# APM32F411 register map
Vendor: Geehy; File version: 2024.11.05
CPU: CM4 r1p0, little endian, 3 interrupt priority bits
Registers are 32-bit, read-write, reset 0x0 unless marked. A register's access mark holds for its fields unless they carry their own. Offsets are from the block's base; [hi:lo] are bit positions; {n}, {i} and the like mark numbered series; 'fields as' and 'values as' point back to an identical list.

## CAN1 — Controller area network
Base 0x40006400
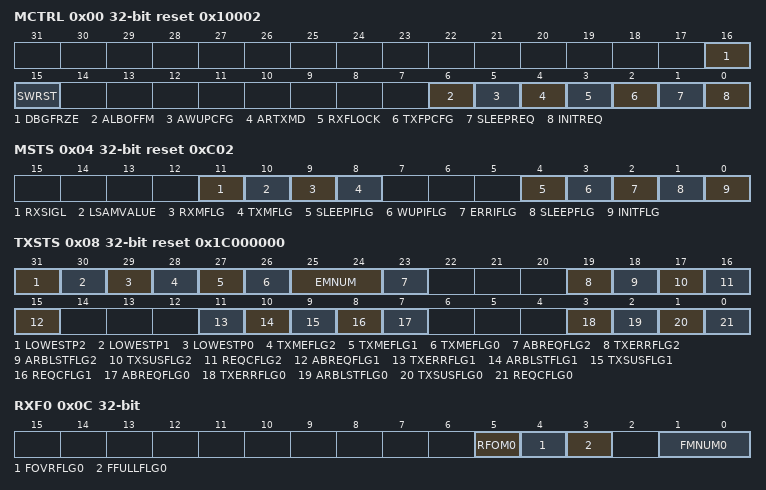
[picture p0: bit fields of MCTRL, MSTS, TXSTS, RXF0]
0x00 MCTRL reset 0x10002 — Governs the CAN controller operation modes and configuration, including initialization/sleep requests, FIFO lock, automatic retransmission, and software reset.
  [16] DBGFRZE — Determines whether the CAN can continue receiving/transmitting during debugging. 0: CAN is active, 1: CAN is frozen (no receive/transmit) but registers remain accessible.
    0=DISABLED (CAN continues normal operation in debug mode.); 1=ENABLED (CAN is frozen (no receive/transmit) during debug mode.)
  [15] SWRST — Forces a reset of the CAN controller when set to 1. Hardware clears this bit automatically once reset is performed, placing CAN in sleep mode.
    0=NO_RESET (Normal operation.); 1=FORCE_RESET (Reset the CAN controller, hardware clears this bit.)
  [6] ALBOFFM — Determines the condition for recovering from bus-off. 0: Software requests init mode then clear it after 128 occurrences of 11 recessive bits. 1: Hardware automatically recovers from bus-off.
    0=SOFTWARE (Need to request init mode and clear it to leave bus-off.); 1=AUTO (Hardware automatically recovers from bus-off.)
  [5] AWUPCFG — Selects how the CAN wakes from sleep mode. 0: Software must clear SLEEPREQ. 1: Hardware automatically clears SLEEPREQ upon detecting CAN traffic.
    0=SW_WAKEUP (Exit from sleep requires software to clear SLEEPREQ bit.); 1=HW_WAKEUP (Automatically exit sleep upon receiving CAN message.)
  [4] ARTXMD — Controls automatic retransmission. 0: Retransmit on error or arbitration loss until success. 1: Transmit only once.
    0=AUTO_RETX_ENABLED (CAN will keep retrying a failed transmission.); 1=AUTO_RETX_DISABLED (Transmit only once, no automatic retry.)
  [3] RXFLOCK — Determines FIFO behavior upon overrun. 0: Overwritten by the new message. 1: New message is discarded when FIFO is full.
    0=UNLOCKED (Overwrite oldest message if FIFO is full.); 1=LOCKED (Discard new message if FIFO is full.)
  [2] TXFPCFG — Determines how priority is chosen when multiple transmit mailboxes are pending. 0: Priority by message identifier (lower ID = higher priority). 1: Priority by transmit request order.
    0=ID_PRIORITY (Use message ID to arbitrate priority.); 1=REQUEST_PRIORITY (Use the sequence of transmission requests.)
  [1] SLEEPREQ — Requests entering sleep mode (1) or exiting it (0). When in sleep mode, the CAN clock stops working, reducing power consumption. If AWUPCFG is set, the controller can automatically clear this bit upon detecting CAN activity.
    0=SLEEPREQ_CLEAR (No sleep request (normal operation).); 1=SLEEPREQ_SET (Request to enter sleep mode.)
  [0] INITREQ — Requests entering initialization mode (1) or exiting it (0). In initialization mode, the CAN configuration (bit timing, filters, etc.) can be modified. Message reception/transmission is disabled in init mode.
    0=NORMAL_MODE (Exit initialization mode.); 1=INIT_MODE (Enter initialization mode.)
0x04 MSTS reset 0xC02 — Reflects the controller's current mode (initialization/sleep), active interrupts, and transmit/receive states. Some flags are set by hardware and cleared by writing 1 (RC_W1).
  [11] RXSIGL ro — Shows the current real-time level of the CAN_RX pin. Set/cleared by hardware.
    0=DOMINANT (Rx pin is currently at a dominant (0) level.); 1=RECESSIVE (Rx pin is currently at a recessive (1) level.)
  [10] LSAMVALUE ro — Displays the last sampled level on the CAN_RX pin. Set/cleared by hardware.
    0=DOMINANT (Sampled a dominant (logic 0) level.); 1=RECESSIVE (Sampled a recessive (logic 1) level.)
  [9] RXMFLG ro — Indicates whether CAN is currently receiving (1) or not (0). Set/cleared by hardware.
    0=NOT_RECEIVING (CAN is not in reception mode.); 1=RECEIVING (CAN is currently receiving a frame.)
  [8] TXMFLG ro — Indicates whether CAN is currently transmitting (1) or not (0). Set/cleared by hardware.
    0=NOT_TRANSMITTING (CAN is not in transmission mode.); 1=TRANSMITTING (CAN is in the process of sending a frame.)
  [4] SLEEPIFLG — Set by hardware when entering sleep mode; cleared by writing 1 or by exiting sleep mode.
    0=NO_SLEEP_INT (Not entered sleep mode or flag cleared.); 1=SLEEP_INT (Entered sleep mode.)
  [3] WUPIFLG — Set by hardware when waking up from sleep mode; cleared by writing 1.
    0=NO_WAKEUP_INT (Did not wake up from sleep or flag cleared.); 1=WAKEUP_INT (CAN woke up from sleep mode.)
  [2] ERRIFLG — Set by hardware when an error interrupt event occurs; cleared by writing 1.
    0=NO_ERROR_INT (No new error interrupt has occurred.); 1=ERROR_INT (An error interrupt event has occurred.)
  [1] SLEEPFLG ro — Indicates whether the CAN is in sleep mode (1) or not (0). Set/cleared by hardware.
    0=AWAKE (CAN is not in sleep mode.); 1=ASLEEP (CAN is in sleep mode.)
  [0] INITFLG ro — Indicates whether the CAN is in initialization mode (1) or not (0). Set/cleared by hardware.
    0=NORMAL_MODE (CAN is not in initialization mode.); 1=INIT_MODE (CAN is in initialization mode.)
0x08 TXSTS access per field reset 0x1C000000 — Provides status for the three transmit mailboxes (request completion, arbitration lost, error flags, abort requests, empty mailboxes, etc.). Certain bits are set or cleared by hardware upon transmission events.
  [31] LOWESTP2 ro — Indicates mailbox 2 is the lowest priority among mailboxes waiting to transmit (only relevant when multiple mailboxes are pending).
    0=NOT_LOWEST (Mailbox 2 is not the lowest priority transmitter); 1=LOWEST (Mailbox 2 is the lowest priority transmitter)
  [30] LOWESTP1 ro — Indicates mailbox 1 is the lowest priority among mailboxes waiting to transmit (only relevant when multiple mailboxes are pending).
    0=NOT_LOWEST (Mailbox 1 is not the lowest priority transmitter); 1=LOWEST (Mailbox 1 is the lowest priority transmitter)
  [29] LOWESTP0 ro — Indicates mailbox 0 is the lowest priority among mailboxes waiting to transmit (only relevant when multiple mailboxes are pending).
    0=NOT_LOWEST (Mailbox 0 is not the lowest priority transmitter); 1=LOWEST (Mailbox 0 is the lowest priority transmitter)
  [28] TXMEFLG2 ro — Set by hardware when mailbox 2 is empty. Cleared by hardware when a message is pending.
    0=NOT_EMPTY (Message pending in mailbox 2); 1=EMPTY (Mailbox 2 contains no message)
  [27] TXMEFLG1 ro — Set by hardware when mailbox 1 is empty. Cleared by hardware when a message is pending.
    0=NOT_EMPTY (Message pending in mailbox 1); 1=EMPTY (Mailbox 1 contains no message)
  [26] TXMEFLG0 ro — Set by hardware when mailbox 0 is empty. Cleared by hardware when a message is pending.
    0=NOT_EMPTY (Message pending in mailbox 0); 1=EMPTY (Mailbox 0 contains no message)
  [25:24] EMNUM ro — Indicates the index of an empty mailbox or the next mailbox to be transmitted if not all are empty.
  [23] ABREQFLG2 rw — Software sets this bit to abort a pending transmit request in mailbox 2. Cleared by hardware when no message is waiting or after successful abort.
    0=NO_ABORT (No abort request); 1=ABORT (Abort the current transmit request)
  [19] TXERRFLG2 rw — Set by hardware when mailbox 2 fails to transmit. Cleared by writing 1.
    0=NO_ERROR (No transmission error); 1=ERROR (Transmission failed for mailbox 2)
  [18] ARBLSTFLG2 rw — Set by hardware if mailbox 2 loses arbitration. Cleared by writing 1.
    0=NO_LOSS (No arbitration lost for mailbox 2); 1=LOST (Mailbox 2 lost arbitration)
  [17] TXSUSFLG2 rw — Set by hardware when the last transmission attempt for mailbox 2 succeeds. Cleared by writing 1.
    0=FAIL (Last attempt failed); 1=SUCCESS (Last attempt succeeded)
  [16] REQCFLG2 rw — Set by hardware when transmission or abort is completed for mailbox 2. Cleared by writing 1.
    0=IN_PROGRESS (Transmission or abort not yet completed); 1=COMPLETED (Transmission or abort completed)
  [15] ABREQFLG1 rw — Software sets this bit to abort a pending transmit request in mailbox 1. Cleared by hardware when no message is waiting or after successful abort.
    values as ABREQFLG2
  [11] TXERRFLG1 rw — Set by hardware when mailbox 1 fails to transmit. Cleared by writing 1.
    0=NO_ERROR (No transmission error); 1=ERROR (Transmission failed for mailbox 1)
  [10] ARBLSTFLG1 rw — Set by hardware if mailbox 1 loses arbitration. Cleared by writing 1.
    0=NO_LOSS (No arbitration lost for mailbox 1); 1=LOST (Mailbox 1 lost arbitration)
  [9] TXSUSFLG1 rw — Set by hardware when the last transmission attempt for mailbox 1 succeeds. Cleared by writing 1.
    values as TXSUSFLG2
  [8] REQCFLG1 rw — Set by hardware when transmission or abort is completed for mailbox 1. Cleared by writing 1.
    values as REQCFLG2
  [7] ABREQFLG0 rw — Software sets this bit to abort a pending transmit request in mailbox 0. Cleared by hardware when no message is waiting or after successful abort.
    values as ABREQFLG2
  [3] TXERRFLG0 rw — Set by hardware when mailbox 0 fails to transmit. Cleared by writing 1.
    0=NO_ERROR (No transmission error); 1=ERROR (Transmission failed for mailbox 0)
  [2] ARBLSTFLG0 rw — Set by hardware if mailbox 0 loses arbitration. Cleared by writing 1.
    0=NO_LOSS (No arbitration lost for mailbox 0); 1=LOST (Mailbox 0 lost arbitration)
  [1] TXSUSFLG0 rw — Set by hardware when the last transmission attempt for mailbox 0 succeeds. Cleared by writing 1.
    values as TXSUSFLG2
  [0] REQCFLG0 rw — Set by hardware when transmission or abort is completed for mailbox 0. Cleared by writing 1.
    values as REQCFLG2
0x0C RXF0 access per field — Reflects the current state of FIFO0, including the number of messages stored, full/overrun flags, and the release output mailbox control.
  [5] RFOM0 rw — If 1, releases the output mailbox of FIFO0, allowing the next stored message to be accessed. Hardware clears this bit to 0 after the release.
    0=NO_RELEASE (Output mailbox is not released.); 1=RELEASE (Frees FIFO0 output mailbox to access next message.)
  [4] FOVRFLG0 rw — Set by hardware when a new message arrives while FIFO0 is full. Cleared by software writing 1.
    0=NO_OVERRUN (No overrun has occurred or flag is cleared.); 1=OVERRUN_OCCURRED (FIFO0 received a new message while already full.)
  [3] FFULLFLG0 rw — Set by hardware when FIFO0 contains three messages. Cleared by software writing 1.
    0=NOT_FULL (FIFO0 is not full.); 1=FULL (FIFO0 contains 3 messages.)
  [1:0] FMNUM0 ro — Reflects the number of messages currently stored in FIFO0 (0..3). Each time a new message is received, this count increases until 3, and it decreases by 1 when the software releases a message from FIFO0.
    0=ZERO_MESSAGES (FIFO0 is empty.); 1=ONE_MESSAGE (FIFO0 contains 1 message.); 2=TWO_MESSAGES (FIFO0 contains 2 messages.); 3=THREE_MESSAGES (FIFO0 contains 3 messages (full).)
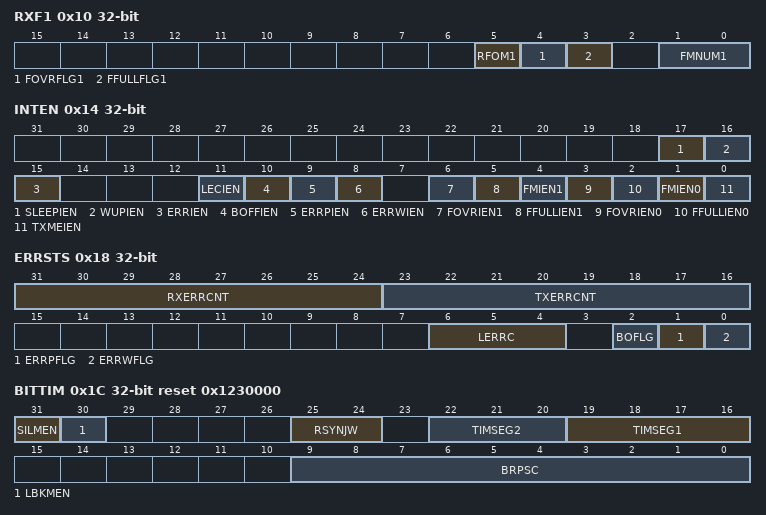
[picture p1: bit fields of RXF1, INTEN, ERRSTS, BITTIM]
0x10 RXF1 access per field — Reflects the current state of FIFO1, including the number of messages stored, full/overrun flags, and the release output mailbox control.
  [5] RFOM1 rw — If 1, releases the output mailbox of FIFO1, allowing the next stored message to be accessed. Hardware clears this bit to 0 after the release.
    0=NO_RELEASE (Output mailbox is not released.); 1=RELEASE (Frees FIFO1 output mailbox to access next message.)
  [4] FOVRFLG1 rw — Set by hardware when a new message arrives while FIFO1 is full. Cleared by software writing 1.
    0=NO_OVERRUN (No overrun has occurred or flag is cleared.); 1=OVERRUN_OCCURRED (FIFO1 received a new message while already full.)
  [3] FFULLFLG1 rw — Set by hardware when FIFO1 contains three messages. Cleared by software writing 1.
    0=NOT_FULL (FIFO1 is not full.); 1=FULL (FIFO1 contains 3 messages.)
  [1:0] FMNUM1 ro — Reflects the number of messages currently stored in FIFO1 (0..3). Each time a new message is received, this count increases until 3, and it decreases by 1 when the software releases a message from FIFO1.
    0=ZERO_MESSAGES (FIFO1 is empty.); 1=ONE_MESSAGE (FIFO1 contains 1 message.); 2=TWO_MESSAGES (FIFO1 contains 2 messages.); 3=THREE_MESSAGES (FIFO1 contains 3 messages (full).)
0x14 INTEN — Enables or disables various CAN interrupt sources, including transmit mailbox empty, receive FIFO events, errors, wake-up and sleep transitions.
  [17] SLEEPIEN — When set, generating an interrupt upon entering sleep mode.
    0=DISABLED (Interrupt generation disabled.); 1=ENABLED (Interrupt generation enabled.)
  [16] WUPIEN — When set, generating an interrupt upon waking up from sleep mode.
    values as SLEEPIEN
  [15] ERRIEN — Global enable for generating error interrupts. If set, the CAN error flags (when the corresponding bits are set) can generate interrupts.
    0=DISABLED (Global error interrupt disabled.); 1=ENABLED (Global error interrupt enabled.)
  [11] LECIEN — When set, generating an error interrupt upon updating the last error code (LERRC).
    values as SLEEPIEN
  [10] BOFFIEN — When set, generating an error interrupt if the CAN enters bus-off status (transmit error counter > 255).
    values as SLEEPIEN
  [9] ERRPIEN — When set, generating an error interrupt if the CAN enters error-passive status (error count > 127).
    values as SLEEPIEN
  [8] ERRWIEN — When set, generating an error interrupt if the CAN enters warning status (error count >= 96).
    values as SLEEPIEN
  [6] FOVRIEN1 — When set, generating an interrupt if FIFO1 receives a new message while already full.
    values as SLEEPIEN
  [5] FFULLIEN1 — When set, generating an interrupt if FIFO1 has reached its full capacity of three messages.
    values as SLEEPIEN
  [4] FMIEN1 — When set, generating an interrupt when the number of messages in FIFO1 becomes nonzero.
    values as SLEEPIEN
  [3] FOVRIEN0 — When set, generating an interrupt if FIFO0 receives a new message while already full.
    values as SLEEPIEN
  [2] FFULLIEN0 — When set, generating an interrupt if FIFO0 has reached its full capacity of three messages.
    values as SLEEPIEN
  [1] FMIEN0 — When set, generating an interrupt when the number of messages in FIFO0 becomes nonzero.
    values as SLEEPIEN
  [0] TXMEIEN — When set, generating an interrupt upon transmission completion (mailbox empty).
    values as SLEEPIEN
0x18 ERRSTS access per field — Reflects various CAN error states and counters, including warning, passive, and bus-off conditions.
  [31:24] RXERRCNT ro — Reflects the current receive error counter. When it exceeds 127, the controller enters error passive.
  [23:16] TXERRCNT ro — Reflects the current transmit error counter. When it exceeds 255, the controller enters bus-off.
  [6:4] LERRC rw — Records the category of the last detected CAN error. Cleared to 0 on successful transmission/reception.
    0=NO_ERROR; 1=BIT_STUFFING_ERROR (Bit stuffing error detected.); 2=FORM_ERROR (Form error detected.); 3=ACK_ERROR (ACK error detected.); 4=RECESSIVE_BIT_ERROR (Recessive bit error detected.); 5=DOMINANT_BIT_ERROR (Dominant bit error detected.); 6=CRC_ERROR (CRC error detected.); 7=SOFTWARE_SET (Bit manually set by software.)
  [2] BOFLG ro — Indicates that the CAN controller has entered bus-off (TX error counter > 255).
    0=ACTIVE (CAN controller is not bus-off.); 1=BUS_OFF (CAN controller is bus-off.)
  [1] ERRPFLG ro — Indicates that the CAN controller has entered error passive (RX or TX error counter > 127).
    0=NO_PASSIVE (No passive error occurred.); 1=PASSIVE (Controller is in error passive state.)
  [0] ERRWFLG ro — Indicates that the CAN controller has reached the error warning level (RX or TX error counter ≥ 96).
    0=NO_WARNING (No error warning occurred.); 1=WARNING (Error warning level reached.)
0x1C BITTIM reset 0x1230000 — Configures the CAN bit timing parameters (such as prescaler and time segments). This register is only accessible in Initialization mode.
  [31] SILMEN — Enables or disables Silent (mute) mode. Valid only while in Initialization mode.
    0=DISABLE (Silent mode disabled (normal operation)); 1=ENABLE (Silent (mute) mode enabled)
  [30] LBKMEN — Enables or disables Loopback mode for CAN self‑test. Valid only while in Initialization mode.
    0=DISABLE (Loopback mode disabled); 1=ENABLE (Loopback mode enabled)
  [25:24] RSYNJW — Configures the resynchronization jump width: tRJW = tCAN x (RSYNJW + 1)
  [22:20] TIMSEG2 — Configures Time Segment 2 (BS2). The duration is tBS2 = tCAN x (TIMSEG2 + 1)
  [19:16] TIMSEG1 — Configures Time Segment 1 (BS1). The duration is tBS1 = tCAN x (TIMSEG1 + 1)
  [9:0] BRPSC — Sets the baud rate prescaler: Tq = (BRPSC + 1) x TPCLK
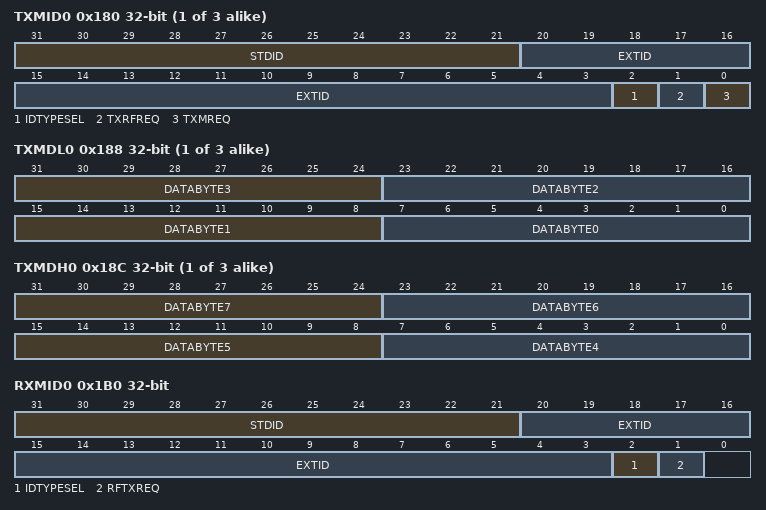
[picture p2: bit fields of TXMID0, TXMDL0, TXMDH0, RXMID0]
{0x180+0x10*i} TXMID{i} (i=0..2) — This register holds the identifier (standard or extended) for the transmitted message, plus bits to request transmission and configure the frame type. It is write-protected while the mailbox is waiting for transmission.
  [31:21] STDID — When IDTYPESEL=0, these 11 bits hold the standard identifier; when IDTYPESEL=1, they hold bits[28:18] of the extended identifier.
  [20:3] EXTID — Holds the lower 18 bits of the extended identifier when IDTYPESEL=1.
  [2] IDTYPESEL — Chooses whether the identifier is standard (11-bit) or extended (29-bit).
    0=STANDARD_ID (Use 11-bit identifier); 1=EXTENDED_ID (Use 29-bit identifier)
  [1] TXRFREQ — Selects whether the transmitted frame is a remote frame (1) or a data frame (0).
    0=DATA_FRAME (Transmit a data frame); 1=REMOTE_FRAME (Transmit a remote frame)
  [0] TXMREQ — Requests transmission from this mailbox. Cleared by hardware when transmission or abort completes.
    0=NO_REQUEST (No transmit request); 1=REQUEST (Request to transmit)
{0x184+0x10*i} TXDLEN{i} (i=0..2) — This register holds the data length code (DLC) for the message to be transmitted from mailbox {i}. When the mailbox is not idle, all bits of this register are write-protected. A maximum of 8 data bytes is supported.
  [3:0] DLCODE — Specifies the length of the data field (0-8 bytes) for the transmitted message.
    0=LEN_0 (Frame has 0 data bytes.); 1=LEN_1 (Frame has 1 data byte.); {v}=LEN_{v} (Frame has {v} data bytes.) (v=2..8)
{0x188+0x10*i} TXMDL{i} (i=0..2) — This register holds data bytes [0..3] for the message to be transmitted from mailbox {i}. When the mailbox is not idle, these bits are write-protected.
  [31:24] DATABYTE3 — Contains the fourth data byte (bits 31..24) of the transmitted message.
  [23:16] DATABYTE2 — Contains the third data byte (bits 23..16) of the transmitted message.
  [15:8] DATABYTE1 — Contains the second data byte (bits 15..8) of the transmitted message.
  [7:0] DATABYTE0 — Contains the first data byte (bits 7..0) of the transmitted message.
{0x18C+0x10*i} TXMDH{i} (i=0..2) — This register holds data bytes [4..7] for the message to be transmitted from mailbox {i}. When the mailbox is not idle, these bits are write-protected.
  [31:24] DATABYTE7 — Contains the seventh data byte (bits 31..24) of the transmitted message.
  [23:16] DATABYTE6 — Contains the sixth data byte (bits 23..16) of the transmitted message.
  [15:8] DATABYTE5 — Contains the fifth data byte (bits 15..8) of the transmitted message.
  [7:0] DATABYTE4 — Contains the fourth data byte (bits 7..0) of the transmitted message.
0x1B0 RXMID0 ro — This register holds the identifier of the message currently at the output of Receive FIFO 0.
  [31:21] STDID — When IDTYPESEL=0, these bits hold the 11-bit standard ID. When IDTYPESEL=1, these bits hold the upper 11 bits [28:18] of the extended ID.
  [20:3] EXTID — When IDTYPESEL=1 (extended ID), these bits hold the lower 18 bits of the 29-bit identifier.
  [2] IDTYPESEL — Indicates whether the message uses a standard 11-bit identifier or an extended 29-bit identifier.
    0=STANDARD (The message uses an 11-bit standard identifier.); 1=EXTENDED (The message uses a 29-bit extended identifier.)
  [1] RFTXREQ — Indicates whether the received frame is a remote frame or a data frame.
    0=DATA (Indicates that this is a data frame.); 1=REMOTE (Indicates that this is a remote frame.)
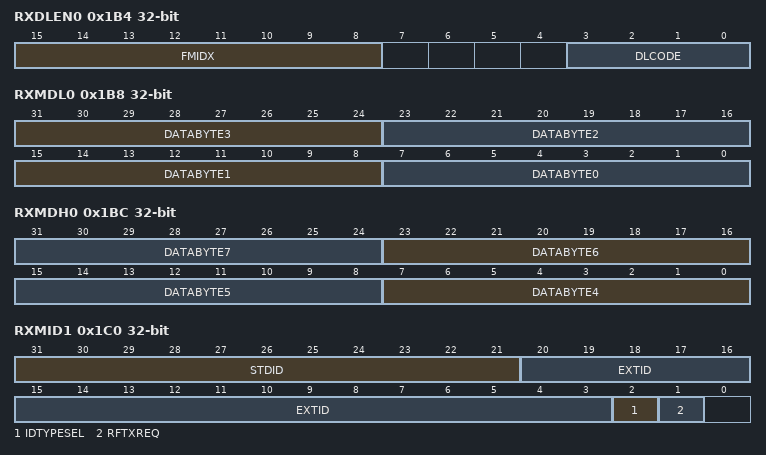
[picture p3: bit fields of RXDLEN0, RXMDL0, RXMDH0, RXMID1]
0x1B4 RXDLEN0 ro — Holds the data length code (DLC) and the filter match index (FMIDX) for the received message in mailbox 0.
  [15:8] FMIDX — Indicates which filter index (0..27) accepted the received message. Values above 27 are possible if multiple filters exist, but only 28 hardware filters are available.
  [3:0] DLCODE — Indicates the number of data bytes (0..8) in the received frame. For a remote frame, DLCODE is always 0.
    0=DL0 (No data bytes (or a remote frame).); 1=DL1 (1 data byte.); {v}=DL{v} ({v} data bytes.) (v=2..8)
0x1B8 RXMDL0 ro — Holds the low data bytes (0..3) of the received message in mailbox 0.
  [31:24] DATABYTE3 — 3rd data byte of the received message.
  [23:16] DATABYTE2 — 2nd data byte of the received message.
  [15:8] DATABYTE1 — 1st data byte of the received message.
  [7:0] DATABYTE0 — 0th data byte of the received message.
0x1BC RXMDH0 ro — Holds the high data bytes (4..7) of the received message in mailbox 0.
  [8n-25:8n-32] DATABYTE{n} (n=4..7) — {n}th data byte of the received message.
0x1C0 RXMID1 ro — This register holds the identifier of the message currently at the output of Receive FIFO 1.
  fields as RXMID0
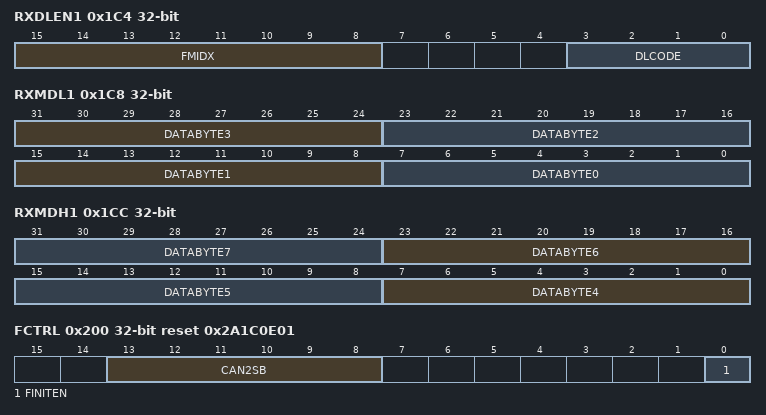
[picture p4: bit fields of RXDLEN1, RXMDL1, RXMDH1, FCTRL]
0x1C4 RXDLEN1 ro — Holds the data length code (DLC) and the filter match index (FMIDX) for the received message in mailbox 1.
  fields as RXDLEN0
0x1C8 RXMDL1 ro — Holds the low data bytes (0..3) of the received message in mailbox 1.
  fields as RXMDL0
0x1CC RXMDH1 ro — Holds the high data bytes (4..7) of the received message in mailbox 1.
  fields as RXMDH0
0x200 FCTRL reset 0x2A1C0E01 — Controls the CAN filter initialization mode and the start bank for CAN2. When FINITEN is set, the filters are in initialization mode (allowing the user to configure them). The CAN2SB bits specify at which filter bank CAN2 begins using filters, effectively splitting the filter banks between CAN1 and CAN2.
  [13:8] CAN2SB — Specifies the first filter bank used by CAN2, in the range 0..27 (or 28 in some devices). A value of 0 means all filter banks belong to CAN2, while a value of 28 can mean all filter banks belong to CAN1. Intermediate values split the filters between CAN1 and CAN2.
    0=ALL_TO_CAN2 (When 0, all filter banks are allocated to CAN2.); 28=ALL_TO_CAN1 (When 28, all filter banks are allocated to CAN1 (if supported on this device).)
  [0] FINITEN — Selects whether the filter unit is placed in initialization mode (1) or normal mode (0). In initialization mode, filter registers can be modified; in normal mode, the filter hardware is active.
    0=NORMAL (Filters operate normally (no initialization).); 1=INIT (Filters remain in initialization mode (registers can be modified).)
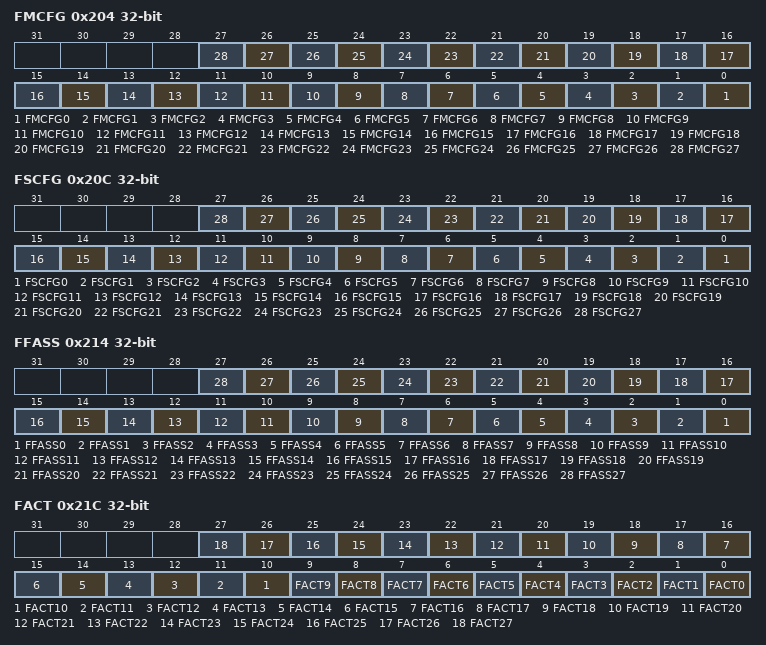
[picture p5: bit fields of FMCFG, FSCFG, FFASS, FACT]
0x204 FMCFG
  [n] FMCFG{n} (n=0..27) — Filter mode
0x20C FSCFG — The CAN_FSCFG register configures the bit width (scale) of each of the 28 CAN filters. Each bit FSCFGx (0 to 27) sets whether the corresponding filter operates in two 16-bit segments (FSCFGx=0) or uses one 32-bit segment (FSCFGx=1). You can modify this register only when filter initialization mode is active (FINITEN bit in CAN_FCTRL = 1).
  [n] FSCFG{n} (n=0..27) — Filter bit
0x214 FFASS — The FFASS register is used to decide whether each of the 28 CAN filters is linked to Receive FIFO 0 or Receive FIFO 1. Each bit FFASSi (where i ranges from 0 to 27) corresponds to a particular filter. If FFASSi is 0, the filter routes matching messages to FIFO 0; if FFASSi is 1, it routes them to FIFO 1. This register can be updated only when the filter initialization mode is enabled (FINITEN bit in CAN_FCTRL = 1).
  [n] FFASS{n} (n=0..27) — Filter FIFO assignment for filter {n}
0x21C FACT — The CAN_FACT register enables or disables each of the 28 CAN filters on a bit-by-bit basis. Each bit FACTi (where i ranges from 0 to 27) corresponds to a specific filter. Setting FACTi to 1 activates that filter, while clearing it to 0 disables the filter. Only filters that are active will be applied when the CAN module checks incoming messages against the configured filter criteria. This register can be modified only when the CAN filter initialization mode (FINITEN in CAN_FCTRL) is enabled or if the filter is deactivated.
  [n] FACT{n} (n=0..27) — Filter active
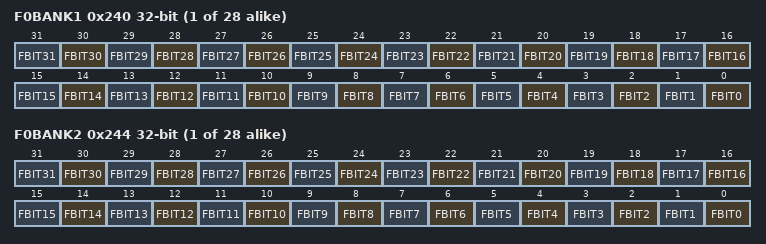
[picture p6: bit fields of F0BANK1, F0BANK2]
{0x240+8i} F{i}BANK1 (i=0..27) — FiBANKx: Filter Bank i Register x (i=0..27, x=1..2). Stores the 32 filter bits for filter bank i (register x). Depending on the filter mode (mask or identifier list) and bit width (16-bit or 32-bit) configured via CAN_FMCFG and CAN_FSCFG, these 32 bits are interpreted either as mask bits or identifier bits for filtering CAN messages. In "identifier mask" mode, a bit of '1' in this register indicates that the corresponding ID bit must match. In "identifier list" mode, these bits form part of the exact ID pattern. The register can only be modified if the filter is in initialization mode (FINITEN=1 in CAN_FCTRL) or if the filter is disabled (FACTx=0). Once activated, the filter logic will use these bits, in conjunction with the other filter bank register (FiBANK1 or FiBANK2), to decide which incoming CAN messages pass to the receive FIFO.
  [n] FBIT{n} (n=0..31) — Filter bits
{0x244+8i} F{i}BANK2 (i=0..27) — FiBANKx: Filter Bank i Register x (i=0..27, x=1..2). Stores the 32 filter bits for filter bank i (register x). Depending on the filter mode (mask or identifier list) and bit width (16-bit or 32-bit) configured via CAN_FMCFG and CAN_FSCFG, these 32 bits are interpreted either as mask bits or identifier bits for filtering CAN messages. In "identifier mask" mode, a bit of '1' in this register indicates that the corresponding ID bit must match. In "identifier list" mode, these bits form part of the exact ID pattern. The register can only be modified if the filter is in initialization mode (FINITEN=1 in CAN_FCTRL) or if the filter is disabled (FACTx=0). Once activated, the filter logic will use these bits, in conjunction with the other filter bank register (FiBANK1 or FiBANK2), to decide which incoming CAN messages pass to the receive FIFO.
  [n] FBIT{n} (n=0..31) — Filter bits

## CAN2 — Controller area network
Base 0x40006800
Registers as CAN1; these are added or differ:
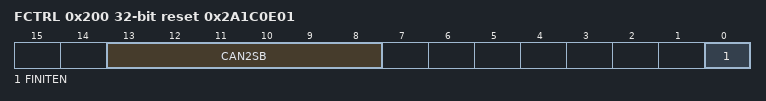
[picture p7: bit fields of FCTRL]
0x200 FCTRL reset 0x2A1C0E01 — Controls the CAN filter initialization mode and the start bank for CAN2. When FINITEN is set, the filters are in initialization mode (allowing the user to configure them). The CAN2SB bits specify at which filter bank CAN2 begins using filters, effectively splitting the filter banks between CAN1 and CAN2.
  fields as CAN1.FCTRL
